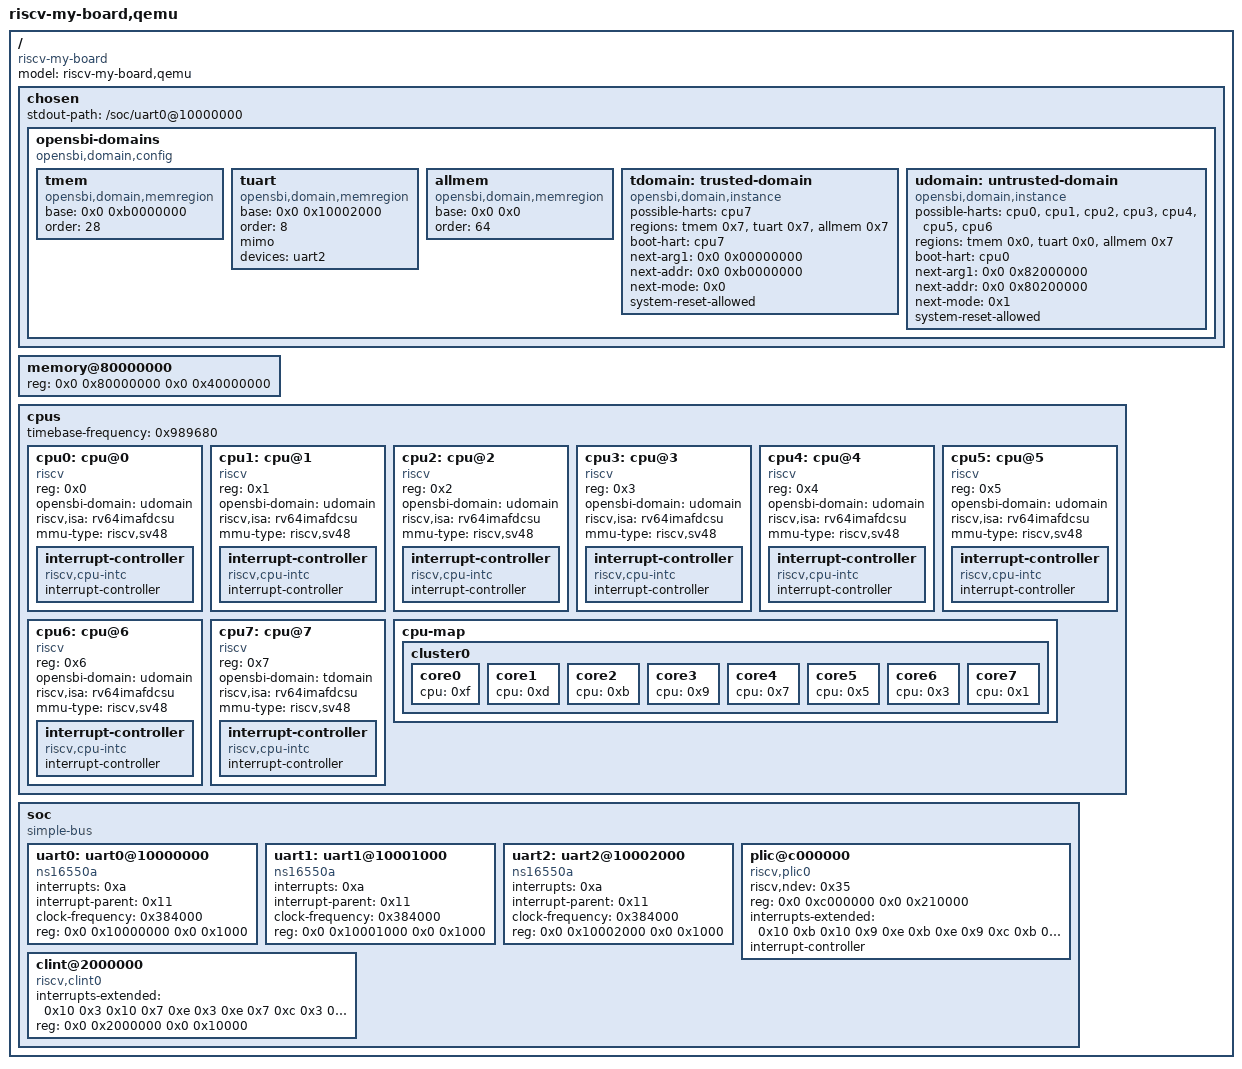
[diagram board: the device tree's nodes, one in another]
/dts-v1/;

/ {
	//地址和大小使用64位表示
	#address-cells = <0x2>;
	#size-cells = <0x2>;
	compatible = "riscv-my-board";
	model = "riscv-my-board,qemu";

    //指定系统的默认输出设备路径为uart0
	chosen {
		stdout-path = "/soc/uart0@10000000";

        //opensbi的domain描述节点
		opensbi-domains {
			compatible = "opensbi,domain,config";
            //定义内存节点，代指某段内存
			tmem: tmem{
				compatible = "opensbi,domain,memregion";//节点属性，opensbi规定
				base = <0x0 0xb0000000>;                //节点起始地址
				order = <28>;                           //节点大小为2^28
			};
			//定义mmio内存节点，代指uart2，mimo表示为内存映射I/O区域
			tuart: tuart{
				compatible = "opensbi,domain,memregion";
				base = <0x0 0x10002000>;
				order = <8>;
				mimo;
				devices = <&uart2>;                      
			};
			//定义内存节点，代指所有内存
			allmem: allmem{
				compatible = "opensbi,domain,memregion";
				base = <0x0 0x0>;
				order = <64>;
			};
			//定义domian节点，该domain节点为trusted-domain
			tdomain: trusted-domain{
				compatible = "opensbi,domain,instance";
				possible-harts = <&cpu7>;                            //允许使用的cpu
				regions = <&tmem 0x7>, <&tuart 0x7>, <&allmem 0x7>;  //各个内存节点的权限
				boot-hart = <&cpu7>;                                 //用于boot的core
				next-arg1 = <0x0 0x00000000>;                        //下级程序的参数
				next-addr = <0x0 0xb0000000>;                        //下级程序的起始地址
				next-mode = <0x0>;                                   //下级程序的允许模式 0为U模式，1为S模式
				system-reset-allowed;                                //允许复位
			};
			//定义domian节点，该domain节点为untrusted-domain
		    udomain: untrusted-domain {
		        compatible = "opensbi,domain,instance";
		        possible-harts = <&cpu0 &cpu1 &cpu2 &cpu3 &cpu4 &cpu5 &cpu6>;
		        regions = <&tmem 0x0>, <&tuart 0x0>, <&allmem 0x7>;
				boot-hart = <&cpu0>;
		        next-arg1 = <0x0 0x82000000>;
		        next-addr = <0x0 0x80200000>;
		        next-mode = <0x1>;
		        system-reset-allowed;
		    };
		};
	};

	//定义物理内存，起始地址为0x80000000，大小为0x40000000（1GB）
	memory@80000000 {
		device_type = "memory";
		reg = <0x0 0x80000000 0x0 0x40000000>;
	};
    //CPU集合，设置各个CPU的属性
	cpus {
		//CPU编号使用32位，大小使用0位，时钟基准为10MHz
		#address-cells = <0x1>;
		#size-cells = <0x0>;
		timebase-frequency = <0x989680>;

		cpu0: cpu@0 {
			phandle = <0xf>;                      //CPU在设备树中的标识符
			device_type = "cpu";                  //声明这是CPU设备
			reg = <0x0>;                          //CPU的编号
			status = "okay";                      //CPU状态，表示被启用
			compatible = "riscv";                 //所属架构
			opensbi-domain = <&udomain>;          //所属domain
			riscv,isa = "rv64imafdcsu";           //指令集属性
			mmu-type = "riscv,sv48";              //内存管理单元属性，使用4级页表，39位虚拟地址空间
            //每个CPU的中断控制器
			interrupt-controller {
				#interrupt-cells = <0x1>;         //中断标识符使用32位
				interrupt-controller;             //声明这是中断控制器
				compatible = "riscv,cpu-intc";    //标识这是riscv架构下的CPU本地中断控制器
				phandle = <0x10>;                 //中断控制器在设备树中的标识符
			};
		};

		cpu1: cpu@1 {
			phandle = <0xd>;
			device_type = "cpu";
			reg = <0x1>;
			status = "okay";
			compatible = "riscv";
			opensbi-domain = <&udomain>;
			riscv,isa = "rv64imafdcsu";
			mmu-type = "riscv,sv48";

			interrupt-controller {
				#interrupt-cells = <0x1>;
				interrupt-controller;
				compatible = "riscv,cpu-intc";
				phandle = <0xe>;
			};
		};

		cpu2: cpu@2 {
			phandle = <0xb>;
			device_type = "cpu";
			reg = <0x2>;
			status = "okay";
			compatible = "riscv";
			opensbi-domain = <&udomain>;
			riscv,isa = "rv64imafdcsu";
			mmu-type = "riscv,sv48";

			interrupt-controller {
				#interrupt-cells = <0x1>;
				interrupt-controller;
				compatible = "riscv,cpu-intc";
				phandle = <0xc>;
			};
		};

		cpu3: cpu@3 {
			phandle = <0x9>;
			device_type = "cpu";
			reg = <0x3>;
			status = "okay";
			compatible = "riscv";
			opensbi-domain = <&udomain>;
			riscv,isa = "rv64imafdcsu";
			mmu-type = "riscv,sv48";

			interrupt-controller {
				#interrupt-cells = <0x1>;
				interrupt-controller;
				compatible = "riscv,cpu-intc";
				phandle = <0xa>;
			};
		};

		cpu4: cpu@4 {
			phandle = <0x7>;
			device_type = "cpu";
			reg = <0x4>;
			status = "okay";
			compatible = "riscv";
			opensbi-domain = <&udomain>;
			riscv,isa = "rv64imafdcsu";
			mmu-type = "riscv,sv48";

			interrupt-controller {
				#interrupt-cells = <0x1>;
				interrupt-controller;
				compatible = "riscv,cpu-intc";
				phandle = <0x8>;
			};
		};

		cpu5: cpu@5 {
			phandle = <0x5>;
			device_type = "cpu";
			reg = <0x5>;
			status = "okay";
			compatible = "riscv";
			opensbi-domain = <&udomain>;
			riscv,isa = "rv64imafdcsu";
			mmu-type = "riscv,sv48";

			interrupt-controller {
				#interrupt-cells = <0x1>;
				interrupt-controller;
				compatible = "riscv,cpu-intc";
				phandle = <0x6>;
			};
		};

		cpu6: cpu@6 {
			phandle = <0x3>;
			device_type = "cpu";
			reg = <0x6>;
			status = "okay";
			compatible = "riscv";
			opensbi-domain = <&udomain>;
			riscv,isa = "rv64imafdcsu";
			mmu-type = "riscv,sv48";

			interrupt-controller {
				#interrupt-cells = <0x1>;
				interrupt-controller;
				compatible = "riscv,cpu-intc";
				phandle = <0x4>;
			};
		};

		cpu7: cpu@7 {
			phandle = <0x1>;
			device_type = "cpu";
			reg = <0x7>;
			status = "okay";
			compatible = "riscv";
			opensbi-domain = <&tdomain>;
			riscv,isa = "rv64imafdcsu";
			mmu-type = "riscv,sv48";

			interrupt-controller {
				#interrupt-cells = <0x1>;
				interrupt-controller;
				compatible = "riscv,cpu-intc";
				phandle = <0x2>;
			};
		};
        //描述CPU的拓扑结构，其中有一个CPU集群，包含8个核心
		cpu-map {

			cluster0 {

				core0 {
					cpu = <0xf>;
				};

				core1 {
					cpu = <0xd>;
				};

				core2 {
					cpu = <0xb>;
				};

				core3 {
					cpu = <0x9>;
				};

				core4 {
					cpu = <0x7>;
				};

				core5 {
					cpu = <0x5>;
				};

				core6 {
					cpu = <0x3>;
				};

				core7 {
					cpu = <0x1>;
				};
			};
		};
	};
    //片上外设
	soc {
		//地址和大小使用64位表示
		#address-cells = <0x2>;
		#size-cells = <0x2>;
		compatible = "simple-bus";
		ranges;                                    
        //串口设备信息，起始地址为10000000
		uart0: uart0@10000000 {
			interrupts = <0xa>;                  //对应中断号
			interrupt-parent = <0x11>;           //所属的中断控制器
			clock-frequency = <0x384000>;        //始终频率
			reg = <0x0 0x10000000 0x0 0x1000>;   //起始地址和大小
			compatible = "ns16550a";             //兼容标准 NS16550A UART
		};

		uart1: uart1@10001000 {
			interrupts = <0xa>;
			interrupt-parent = <0x11>;
			clock-frequency = <0x384000>;
			reg = <0x0 0x10001000 0x0 0x1000>;
			compatible = "ns16550a";
		};

        uart2: uart2@10002000 {
			interrupts = <0xa>;
			interrupt-parent = <0x11>;
			clock-frequency = <0x384000>;
			reg = <0x0 0x10002000 0x0 0x1000>;
			compatible = "ns16550a";
		};
        //plic设备信息，起始地址为c000000
		plic@c000000 {
			phandle = <0x11>;                    //plic在设备树中的标识符
			riscv,ndev = <0x35>;                 //支持的最大外部中断源的数量
			reg = <0x0 0xc000000 0x0 0x210000>;  //起始地址和大小
			//各个CPU对应的外部中断号，格式为<CPU句柄 中断号 CPU句柄 中断号 ...>
			interrupts-extended = <0x10 0xb 0x10 0x9 0xe 0xb 0xe 0x9 0xc 0xb 0xc 0x9 0xa 0xb 0xa 0x9 0x8 0xb 0x8 0x9 0x6 0xb 0x6 0x9 0x4 0xb 0x4 0x9 0x2 0xb 0x2 0x9>;
			interrupt-controller;                //声明此节点为中断控制器
			compatible = "riscv,plic0";          //标识这是一个符合riscv架构的plic
			#interrupt-cells = <0x1>;            //同上
			#address-cells = <0x0>;              //同上
		};
        //clint设备信息，起始地址为2000000
		clint@2000000 {
            //各个CPU对应的定时器中断号和核间中断号
			interrupts-extended = <0x10 0x3 0x10 0x7 0xe 0x3 0xe 0x7 0xc 0x3 0xc 0x7 0xa 0x3 0xa 0x7 0x8 0x3 0x8 0x7 0x6 0x3 0x6 0x7 0x4 0x3 0x4 0x7 0x2 0x3 0x2 0x7>;
			reg = <0x0 0x2000000 0x0 0x10000>;   //起始地址和大小
			compatible = "riscv,clint0";         //标识这是一个符合riscv架构的clint
		};
	};
};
